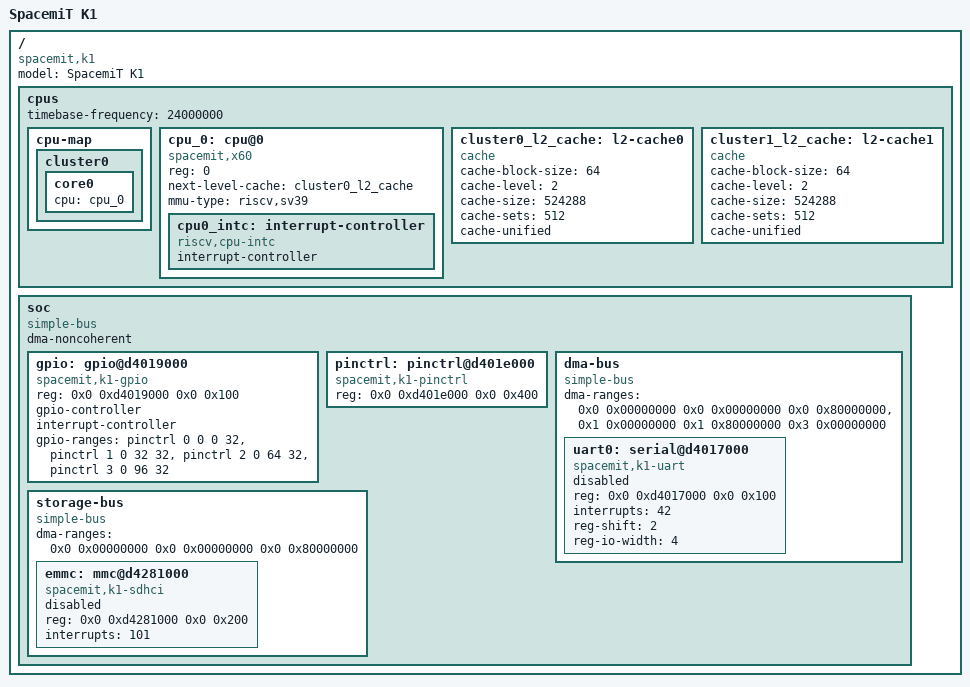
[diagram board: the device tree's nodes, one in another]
// SPDX-License-Identifier: GPL-2.0 OR MIT
/*
 * Copyright (C) 2024 Yangyu Chen <cyy@cyyself.name>
 */

#include <dt-bindings/clock/spacemit,k1-syscon.h>

/dts-v1/;
/ {
	#address-cells = <2>;
	#size-cells = <2>;
	model = "SpacemiT K1";
	compatible = "spacemit,k1";

	cpus {
		#address-cells = <1>;
		#size-cells = <0>;
		timebase-frequency = <24000000>;

		cpu-map {
			cluster0 {
				core0 {
					cpu = <&cpu_0>;
				};
			};
		};

		cpu_0: cpu@0 {
			compatible = "spacemit,x60", "riscv";
			device_type = "cpu";
			reg = <0>;
			next-level-cache = <&cluster0_l2_cache>;
			mmu-type = "riscv,sv39";

			cpu0_intc: interrupt-controller {
				compatible = "riscv,cpu-intc";
				interrupt-controller;
				#interrupt-cells = <1>;
			};
		};

		cluster0_l2_cache: l2-cache0 {
			compatible = "cache";
			cache-block-size = <64>;
			cache-level = <2>;
			cache-size = <524288>;
			cache-sets = <512>;
			cache-unified;
		};

		cluster1_l2_cache: l2-cache1 {
			compatible = "cache";
			cache-block-size = <64>;
			cache-level = <2>;
			cache-size = <524288>;
			cache-sets = <512>;
			cache-unified;
		};
	};

	soc {
		compatible = "simple-bus";
		//interrupt-parent = <&plic>;
		#address-cells = <2>;
		#size-cells = <2>;
		dma-noncoherent;
		ranges;


		gpio: gpio@d4019000 {
			compatible = "spacemit,k1-gpio";
			reg = <0x0 0xd4019000 0x0 0x100>;
			//clocks = <&syscon_apbc CLK_GPIO>,
			//	 <&syscon_apbc CLK_GPIO_BUS>;
			clock-names = "core", "bus";
			gpio-controller;
			#gpio-cells = <3>;
			//interrupts = <58>;
			//interrupt-parent = <&plic>;
			interrupt-controller;
			#interrupt-cells = <3>;
			gpio-ranges = <&pinctrl 0 0 0 32>,
				      <&pinctrl 1 0 32 32>,
				      <&pinctrl 2 0 64 32>,
				      <&pinctrl 3 0 96 32>;
		};

		pinctrl: pinctrl@d401e000 {
			compatible = "spacemit,k1-pinctrl";
			reg = <0x0 0xd401e000 0x0 0x400>;
			//clocks = <&syscon_apbc CLK_AIB>,
			//	 <&syscon_apbc CLK_AIB_BUS>;
			clock-names = "func", "bus";
		};


		dma-bus {
			compatible = "simple-bus";
			ranges;
			#address-cells = <2>;
			#size-cells = <2>;
			dma-ranges = <0x0 0x00000000 0x0 0x00000000 0x0 0x80000000>,
				     <0x1 0x00000000 0x1 0x80000000 0x3 0x00000000>;
			uart0: serial@d4017000 {
				compatible = "spacemit,k1-uart",
					     "intel,xscale-uart";
				reg = <0x0 0xd4017000 0x0 0x100>;
				//clocks = <&syscon_apbc CLK_UART0>,
				//	 <&syscon_apbc CLK_UART0_BUS>;
				clock-names = "core", "bus";
				//resets = <&syscon_apbc RESET_UART0>;
				interrupts = <42>;
				reg-shift = <2>;
				reg-io-width = <4>;
				status = "disabled";
			};
		};
	
		storage-bus {
			compatible = "simple-bus";
			ranges;
			#address-cells = <2>;
			#size-cells = <2>;
			dma-ranges = <0x0 0x00000000 0x0 0x00000000 0x0 0x80000000>;

			emmc: mmc@d4281000 {
				compatible = "spacemit,k1-sdhci";
				reg = <0x0 0xd4281000 0x0 0x200>;
				//clocks = <&syscon_apmu CLK_SDH_AXI>,
				//	 <&syscon_apmu CLK_SDH2>;
				clock-names = "core", "io";
				interrupts = <101>;
				status = "disabled";
			};
		};
	};
};
